# M066 register map
File version: 0.1
Registers are 32-bit, read-write, reset 0x0 unless marked. A register's access mark holds for its fields unless they carry their own. Offsets are from the block's base; [hi:lo] are bit positions; {n}, {i} and the like mark numbered series.

## PG — Port G
Base 0x400C0600
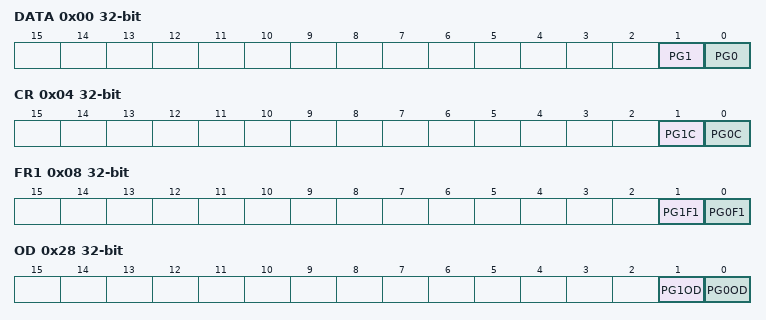
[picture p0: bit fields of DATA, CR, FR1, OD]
0x00 DATA — PG Data Register
  [1] PG1, [0] PG0
0x04 CR — PG Control Register
  [1] PG1C, [0] PG0C
0x08 FR1 — PG Function Register 1
  [1] PG1F1, [0] PG0F1
0x28 OD — PG Open Drain Control Register
  [1] PG1OD, [0] PG0OD
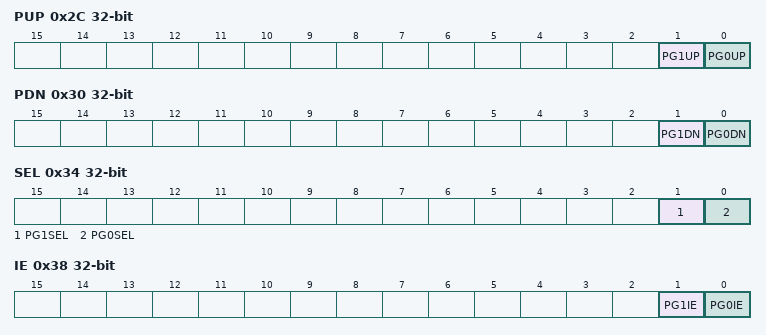
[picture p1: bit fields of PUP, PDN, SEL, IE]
0x2C PUP — PG Pull-up Control Register
  [1] PG1UP, [0] PG0UP
0x30 PDN — PG Pull-Down Control Register
  [1] PG1DN, [0] PG0DN
0x34 SEL — PG input voltage selection Register
  [1] PG1SEL, [0] PG0SEL
0x38 IE — PG Input Enable Control Register
  [1] PG1IE, [0] PG0IE

## PH — Port H
Base 0x400C0700
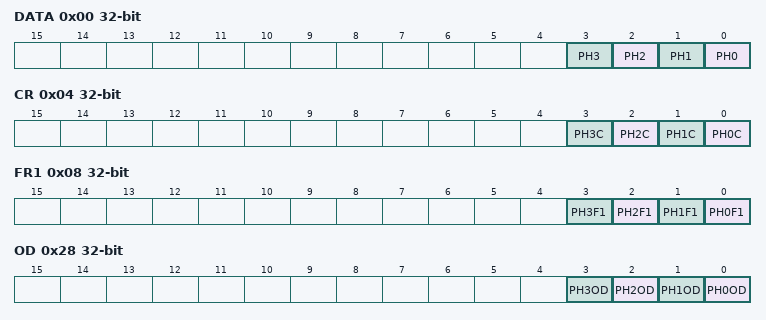
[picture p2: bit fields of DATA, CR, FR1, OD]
0x00 DATA — PH Data Register
  [n] PH{n} (n=0..3)
0x04 CR — PH Control Register
  [n] PH{n}C (n=0..3)
0x08 FR1 — PF Function Register 1
  [n] PH{n}F1 (n=0..3)
0x28 OD — PH Open Drain Control Register
  [n] PH{n}OD (n=0..3)
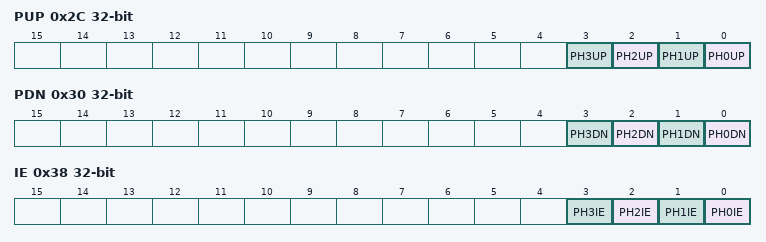
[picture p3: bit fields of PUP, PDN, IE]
0x2C PUP — PH Pull-up Control Register
  [n] PH{n}UP (n=0..3)
0x30 PDN — PH Pull-Down Control Register
  [n] PH{n}DN (n=0..3)
0x38 IE — PH Input Enable Control Register
  [n] PH{n}IE (n=0..3)

## PJ — Port J
Base 0x400C0800
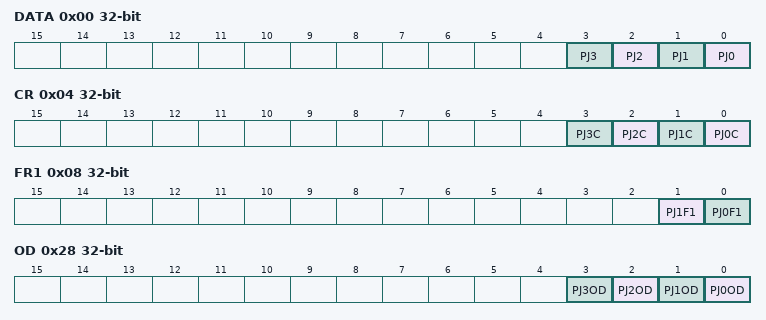
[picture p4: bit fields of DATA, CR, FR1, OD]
0x00 DATA — PJ Data Register
  [n] PJ{n} (n=0..3)
0x04 CR — PJ Control Register
  [n] PJ{n}C (n=0..3)
0x08 FR1 — PJ Function Register 1
  [1] PJ1F1, [0] PJ0F1
0x28 OD — PJ Open Drain Control Register
  [n] PJ{n}OD (n=0..3)
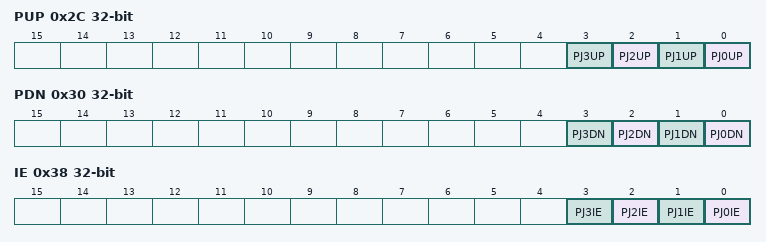
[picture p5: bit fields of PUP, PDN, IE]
0x2C PUP — PJ Pull-up Control Register
  [n] PJ{n}UP (n=0..3)
0x30 PDN — PJ Pull-Down Control Register
  [n] PJ{n}DN (n=0..3)
0x38 IE — PJ Input Enable Control Register
  [n] PJ{n}IE (n=0..3)

## TB0 — 16-bit Timer_Event Counter (TB)
Base 0x400C4000
Same registers: TB1 0x400C4100, TB2 0x400C4200, TB3 0x400C4300, TB4 0x400C4400, TB5 0x400C4500, TB6 0x400C4600, TB7 0x400C4700
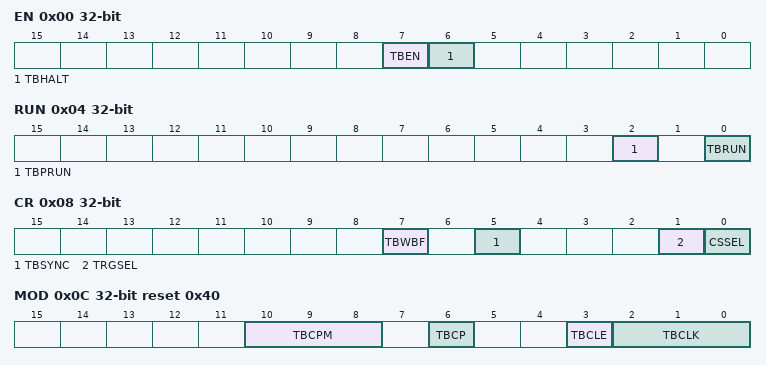
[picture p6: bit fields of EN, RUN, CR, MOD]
0x00 EN — TB Enable Register
  [7] TBEN, [6] TBHALT
0x04 RUN — TB RUN Register
  [2] TBPRUN, [0] TBRUN
0x08 CR — TB Control Register
  [7] TBWBF, [5] TBSYNC, [1] TRGSEL, [0] CSSEL
0x0C MOD reset 0x40 — TB Mode Register
  [10:8] TBCPM, [6] TBCP wo, [3] TBCLE, [2:0] TBCLK
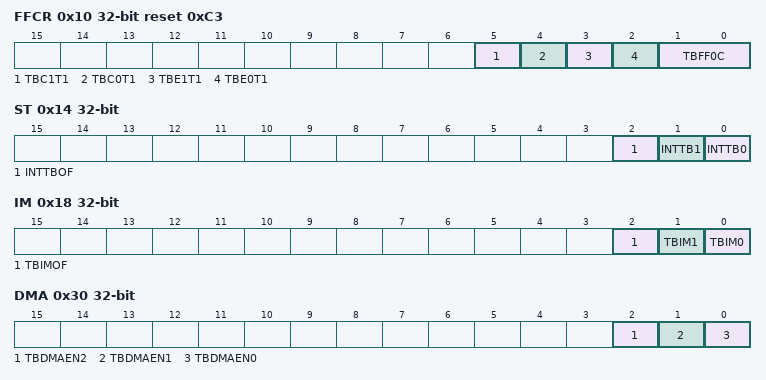
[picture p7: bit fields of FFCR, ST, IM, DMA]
0x10 FFCR reset 0xC3 — TB Flip-Flop Control Register
  [5] TBC1T1, [4] TBC0T1, [3] TBE1T1, [2] TBE0T1, [1:0] TBFF0C
0x14 ST ro — TB Status Register
  [2] INTTBOF, [1] INTTB1, [0] INTTB0
0x18 IM — TB Interrupt Mask Register
  [2] TBIMOF, [1] TBIM1, [0] TBIM0
0x1C UC ro — TB Read Capture Register
  [15:0] TBUC
0x20 RG0 — TB RG0 Timer Register
  [15:0] TBRG0
0x24 RG1 — TB RG1 Timer Register
  [15:0] TBRG1
0x28 CP0 ro (reset mask 0xFFFF0000) — TB CP0 Capture Register
  [15:0] TBCP0
0x2C CP1 ro (reset mask 0xFFFF0000) — TB CP1 Capture Register
  [15:0] TBCP1
0x30 DMA — TB DMA Enable Register
  [2] TBDMAEN2, [1] TBDMAEN1, [0] TBDMAEN0

## SC0 — SC
Base 0x400E1000
Same registers: SC1 0x400E1100
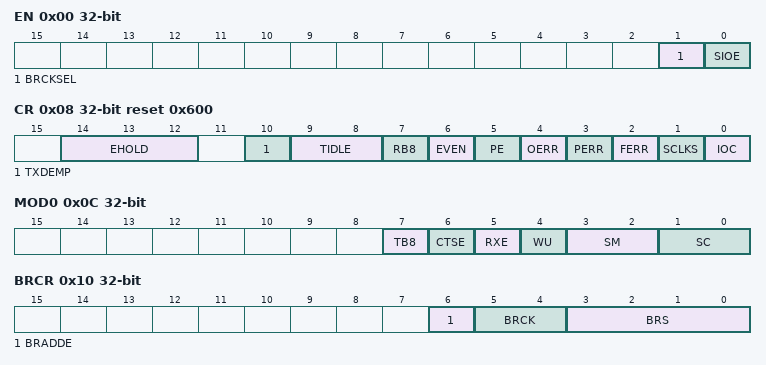
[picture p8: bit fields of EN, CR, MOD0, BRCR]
0x00 EN — SC Enable Register
  [1] BRCKSEL, [0] SIOE
0x04 BUF — SC Buffer Register
  [7:0] TB_RB
0x08 CR reset 0x600 — SC Control Register
  [14:12] EHOLD, [10] TXDEMP, [9:8] TIDLE, [7] RB8 ro, [6] EVEN, [5] PE, [4] OERR ro, [3] PERR ro, [2] FERR ro, [1] SCLKS, [0] IOC
0x0C MOD0 — SC Mode Control Register 0
  [7] TB8, [6] CTSE, [5] RXE, [4] WU, [3:2] SM, [1:0] SC
0x10 BRCR — SC Baud Rate Generator Control Register
  [6] BRADDE, [5:4] BRCK, [3:0] BRS
0x14 BRADD — SC Baud Rate Generator Control Register 2
  [3:0] BRK
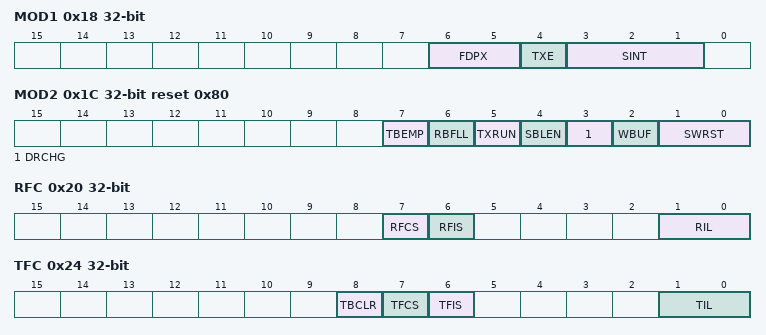
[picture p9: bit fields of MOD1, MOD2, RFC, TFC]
0x18 MOD1 — SC Mode Control Register 1
  [6:5] FDPX, [4] TXE, [3:1] SINT
0x1C MOD2 reset 0x80 — SC Mode Control Register 2
  [7] TBEMP ro, [6] RBFLL ro, [5] TXRUN ro, [4] SBLEN, [3] DRCHG, [2] WBUF, [1:0] SWRST
0x20 RFC — SC RX FIFO Configuration Register
  [7] RFCS wo, [6] RFIS, [1:0] RIL
0x24 TFC — SC TX FIFO Configuration Register
  [8] TBCLR wo, [7] TFCS wo, [6] TFIS, [1:0] TIL
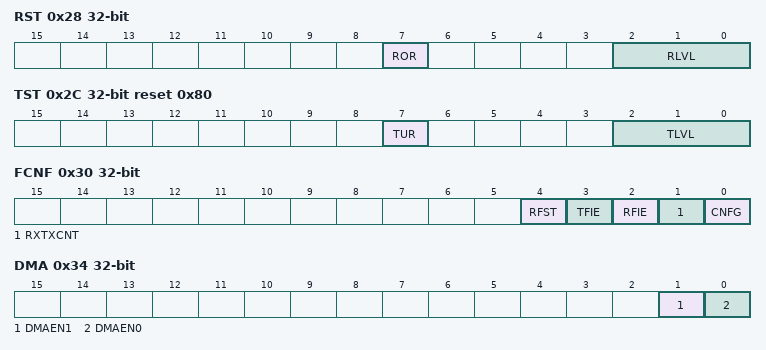
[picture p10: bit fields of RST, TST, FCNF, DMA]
0x28 RST ro — SC RX FIFO Status Register
  [7] ROR, [2:0] RLVL
0x2C TST ro reset 0x80 — SC TX FIFO Status Register
  [7] TUR, [2:0] TLVL
0x30 FCNF — SC FIFO Configuration Register
  [4] RFST, [3] TFIE, [2] RFIE, [1] RXTXCNT, [0] CNFG
0x34 DMA — SC DMA Request Register
  [1] DMAEN1, [0] DMAEN0

## WD — WDT
Base 0x400F2000
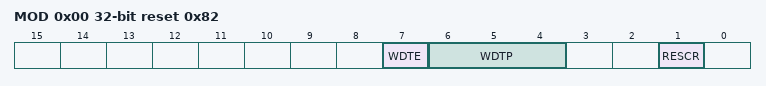
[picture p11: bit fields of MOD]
0x00 MOD reset 0x82 — WD Mode Register
  [7] WDTE, [6:4] WDTP, [1] RESCR
0x04 CR wo (reset mask 0xFFFFFF00) — WD Control Register
  [7:0] WDCR
0x08 FLG ro (reset mask 0xFFFFFFFE) — WD Flag Register
  [0] FLG

## CG
Base 0x400F3000
0x00 PROTECT
  [7:0] PROTECT
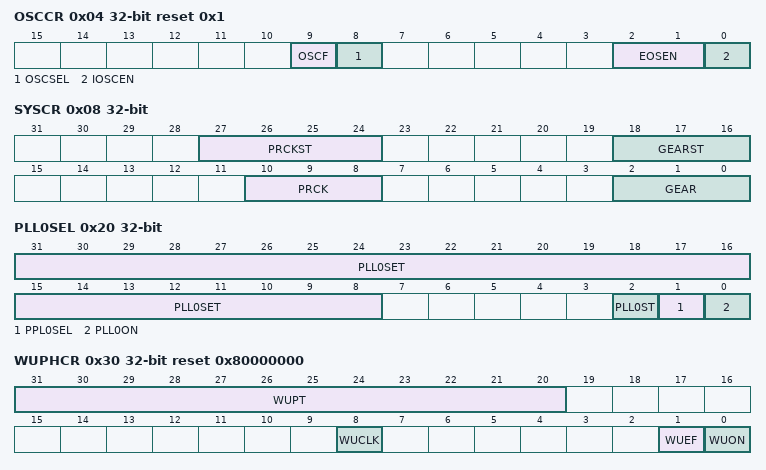
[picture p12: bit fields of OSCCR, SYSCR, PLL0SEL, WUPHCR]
0x04 OSCCR reset 0x1 — Oscillation Control Register
  [9] OSCF ro, [8] OSCSEL, [2:1] EOSEN, [0] IOSCEN
0x08 SYSCR — System clock control register
  [27:24] PRCKST ro, [18:16] GEARST ro, [10:8] PRCK, [2:0] GEAR
0x0C STBYCR — Standby Control Register
  [1:0] STBY
0x20 PLL0SEL — PLL select register for fsys
  [31:8] PLL0SET, [2] PLL0ST, [1] PPL0SEL, [0] PLL0ON
0x30 WUPHCR reset 0x80000000 — Warmup register for HOSC
  [31:20] WUPT, [8] WUCLK, [1] WUEF ro, [0] WUON wo
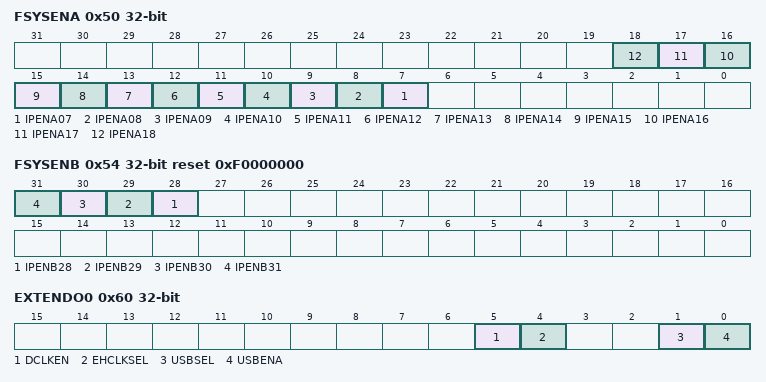
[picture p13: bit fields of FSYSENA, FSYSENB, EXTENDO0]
0x50 FSYSENA — output control register A for fsys clock
  [n] IPENA{n:02} (n=7..18)
0x54 FSYSENB wo reset 0xF0000000 — output control register B for fsys clock
  [n] IPENB{n} rw (n=28..31)
0x5C SPCLKEN — Output control register for ADC and TRACE CLOCK
  [16] ADCKEN
0x60 EXTENDO0 — Optional Function setting Register
  [5] DCLKEN, [4] EHCLKSEL, [1] USBSEL, [0] USBENA

## LVD
Base 0x400F4000
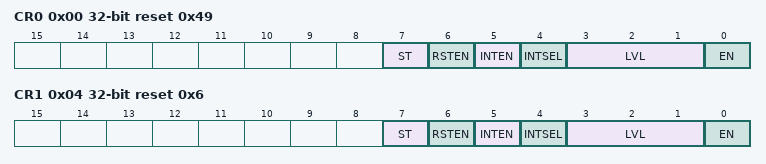
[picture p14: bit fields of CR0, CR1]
0x00 CR0 reset 0x49 — LVD Control register0
  [7] ST ro, [6] RSTEN, [5] INTEN, [4] INTSEL, [3:1] LVL, [0] EN
0x04 CR1 reset 0x6 — LVD Control register1
  [7] ST ro, [6] RSTEN, [5] INTEN, [4] INTSEL, [3:1] LVL, [0] EN

## INTIFSD — SD Area register1
Base 0x400F4E00
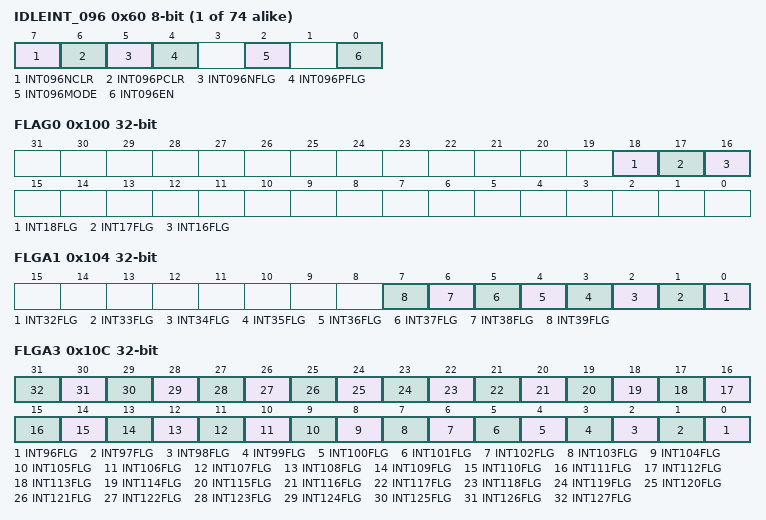
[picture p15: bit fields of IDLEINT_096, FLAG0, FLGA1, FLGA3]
{0x0+i} IDLEINT_{i:03} 8-bit (i=96..169) — IDLEINT I_F Control Register in SD Area
  [7] INT{i:03}NCLR, [6] INT{i:03}PCLR, [5] INT{i:03}NFLG, [4] INT{i:03}PFLG, [2] INT{i:03}MODE, [0] INT{i:03}EN
0x100 FLAG0 ro — NMI interrupt status flag register
  [18] INT18FLG, [17] INT17FLG, [16] INT16FLG
0x104 FLGA1 ro — interrupt status flag register1 for AO area
  [n-32] INT{n}FLG (n=32..39)
0x10C FLGA3 ro — interrupt status flag register3 for SD area
  [n-96] INT{n}FLG (n=96..127)
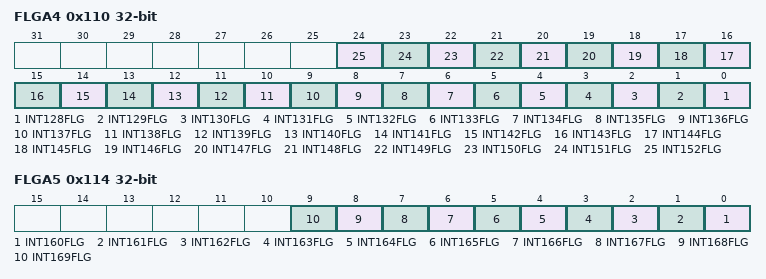
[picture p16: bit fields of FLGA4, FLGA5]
0x110 FLGA4 ro — interrupt status flag register4 for SD area
  [n-128] INT{n}FLG (n=128..152)
0x114 FLGA5 ro — interrupt status flag register5 for SD area
  [n-160] INT{n}FLG (n=160..169)

## AD — ADC
Base 0x400FC000
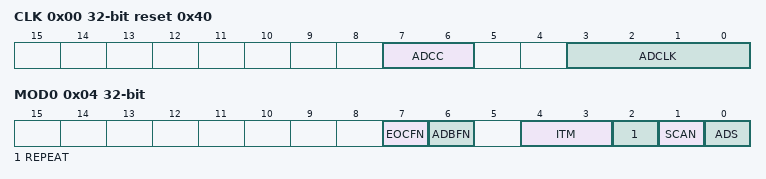
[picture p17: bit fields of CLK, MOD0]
0x00 CLK reset 0x40 — AD Conversion Clock Setting Register
  [7:6] ADCC, [3:0] ADCLK
0x04 MOD0 — AD Mode Control Register 0
  [7] EOCFN ro, [6] ADBFN ro, [4:3] ITM, [2] REPEAT, [1] SCAN, [0] ADS wo
0x08 MOD1 — AD Mode Control Register 1
  [7] VREFON, [6] I2AD, [5:4] ADSCN, [3:0] ADCH
0x0C MOD2 — AD Mode Control Register 2
  [7] EOCFHP ro, [6] ADBFHP ro, [5] HPADCE wo, [3:0] HPADCH
0x10 MOD3 — AD Mode Control Register 3
  [5] ADOBIC0, [4:1] ADREGS0, [0] ADOBSV0
0x14 MOD4 — AD Mode Control Register 4
  [7] HADHS, [6] HADHTG, [5] ADHS, [4] ADHTG, [1:0] ADRST wo
0x18 MOD5 — AD Mode Control Register 5
  [5] ADOBIC1, [4:1] ADREGS1, [0] ADOBSV1
0x1C MOD6 — AD Mode Control Register 6
  [3] ADM1DMA, [2] ADM0DMA, [1] ADHPDMA, [0] ADDMA
{0x30+4i} REG{i} ro (i=0..7) — AD Conversion Result Register {i}
  [15:6] ADR{i}, [1] OVR{i}, [0] ADR{i}RF
0x60 REGSP ro — AD Conversion Result Register SP
  [15:6] ADRSP, [1] OBRSP, [0] ADRSPRF
0x64 CMP0 — AD Conversion Result comparing register0
  [15:6] ADCOM0
0x68 CMP1 — AD Conversion result comparing register1
  [15:6] ADCOM1

## FC
Base 0x41FFF000
0x10 SECBIT reset 0x1 — FC Security Bit Register
  [0] SECBIT
0x20 SR ro reset 0x1 — FC Flash Status Register
  [0] RDY_BSY
0x30 PSRA ro (reset mask 0xFFFFFFF0) — FC Protect status register
  [n] BLK{n} (n=0..3)
0x38 PMRA reset 0xF — FC Protect Mask register
  [n] BLKM{n} (n=0..3)
